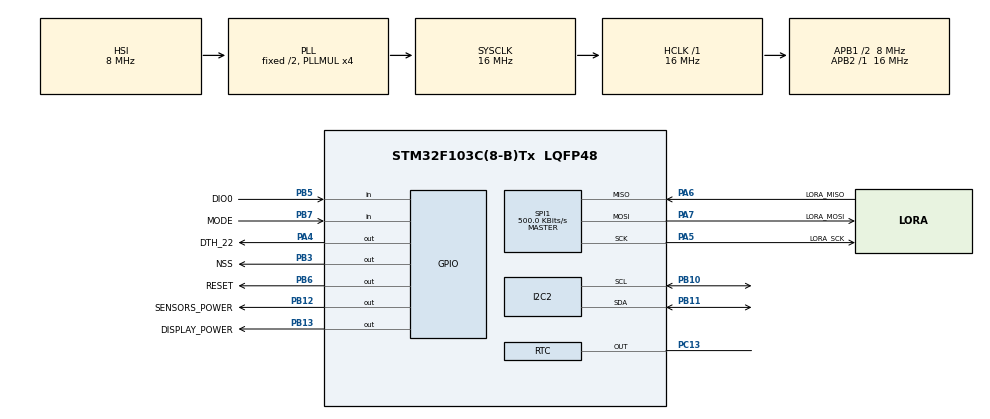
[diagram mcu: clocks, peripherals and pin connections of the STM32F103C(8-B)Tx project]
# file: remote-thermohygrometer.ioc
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Mcu.Family=STM32F1
Mcu.Name=STM32F103C(8-B)Tx
Mcu.Package=LQFP48
NVIC.PriorityGroup=NVIC_PRIORITYGROUP_4
PA0-WKUP.GPIO_Label=SYSTEM_WAKEUP
PA0-WKUP.Mode=SYS_WakeUp0
PA0-WKUP.Signal=SYS_WKUP
PA13.Mode=Serial_Wire
PA13.Signal=SYS_JTMS-SWDIO
PA14.Mode=Serial_Wire
PA14.Signal=SYS_JTCK-SWCLK
PA4.GPIO_Label=DTH_22
PA4.Signal=GPIO_Output
PA5.GPIO_Label=LORA_SCK
PA5.Mode=Full_Duplex_Master
PA5.Signal=SPI1_SCK
PA6.GPIO_Label=LORA_MISO
PA6.Mode=Full_Duplex_Master
PA6.Signal=SPI1_MISO
PA7.GPIO_Label=LORA_MOSI
PA7.Mode=Full_Duplex_Master
PA7.Signal=SPI1_MOSI
PB10.Mode=I2C
PB10.Signal=I2C2_SCL
PB11.Mode=I2C
PB11.Signal=I2C2_SDA
PB12.GPIO_Label=SENSORS_POWER
PB12.Signal=GPIO_Output
PB13.GPIO_Label=DISPLAY_POWER
PB13.Signal=GPIO_Output
PB3.GPIO_Label=NSS
PB3.PinState=GPIO_PIN_SET
PB3.Signal=GPIO_Output
PB5.GPIO_Label=DIO0
PB5.Signal=GPIO_Input
PB6.GPIO_Label=RESET
PB6.PinState=GPIO_PIN_SET
PB6.Signal=GPIO_Output
PB7.GPIO_Label=MODE
PB7.GPIO_PuPd=GPIO_PULLDOWN
PB7.Signal=GPIO_Input
PC13-TAMPER-RTC.Mode=RTC OUT
PC13-TAMPER-RTC.Signal=RTC_OUT
PD0-OSC_IN.Mode=HSE-External-Clock-Source
PD0-OSC_IN.Signal=RCC_OSC_IN
PD1-OSC_OUT.Mode=HSE-External-Clock-Source
PD1-OSC_OUT.Signal=RCC_OSC_OUT
ProjectManager.HeapSize=0x200
ProjectManager.StackSize=0x400
ProjectManager.TargetToolchain=STM32CubeIDE
RCC.AHBFreq_Value=16000000
RCC.APB1CLKDivider=RCC_HCLK_DIV2
RCC.APB1Freq_Value=8000000
RCC.APB1TimFreq_Value=16000000
RCC.APB2Freq_Value=16000000
RCC.APB2TimFreq_Value=16000000
RCC.HCLKFreq_Value=16000000
RCC.PLLMUL=RCC_PLL_MUL4
RCC.SYSCLKFreq_VALUE=16000000
RCC.SYSCLKSource=RCC_SYSCLKSOURCE_PLLCLK
RCC.USBFreq_Value=16000000
RTC.Minutes_A-RTC\ OUT=1
RTC.Seconds_A-RTC\ OUT=0
SPI1.BaudRatePrescaler=SPI_BAUDRATEPRESCALER_32
SPI1.CalculateBaudRate=500.0 KBits/s
SPI1.Direction=SPI_DIRECTION_2LINES
SPI1.Mode=SPI_MODE_MASTER
SPI1.VirtualType=VM_MASTER
TIM1.Prescaler=16-1
VP_RTC_VS_RTC_Activate.Mode=RTC_Enabled
VP_RTC_VS_RTC_Calendar.Mode=RTC_Calendar
VP_TIM1_VS_ClockSourceINT.Mode=Internal
board=custom

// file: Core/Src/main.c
/* USER CODE BEGIN Header */
/**
  ******************************************************************************
  * @file           : main.c
  * @brief          : Main program body
  ******************************************************************************
  * @attention
  *
  * Copyright (c) 2024 STMicroelectronics.
  * All rights reserved.
  *
  * This software is licensed under terms that can be found in the LICENSE file
  * in the root directory of this software component.
  * If no LICENSE file comes with this software, it is provided AS-IS.
  *
  ******************************************************************************
  */
/* USER CODE END Header */
#include "main.h"

/* USER CODE BEGIN Includes */
#include "App/app.h"
/* USER CODE END Includes */

I2C_HandleTypeDef hi2c2;

RTC_HandleTypeDef hrtc;

SPI_HandleTypeDef hspi1;

TIM_HandleTypeDef htim1;

void SystemClock_Config(void);
static void MX_GPIO_Init(void);
static void MX_SPI1_Init(void);
static void MX_I2C2_Init(void);
static void MX_TIM1_Init(void);
static void MX_RTC_Init(void);

int main(void)
{

  /* MCU Configuration--------------------------------------------------------*/

  /* Reset of all peripherals, Initializes the Flash interface and the Systick. */
  HAL_Init();

  /* Configure the system clock */
  SystemClock_Config();

  /* Initialize all configured peripherals */
  MX_GPIO_Init();
  MX_SPI1_Init();
  MX_I2C2_Init();
  MX_TIM1_Init();
  MX_RTC_Init();
  /* USER CODE BEGIN 2 */

  __HAL_PWR_CLEAR_FLAG(PWR_FLAG_WU);

  HAL_TIM_Base_Start(&htim1);
  appMain(&hi2c2, &hspi1);

  HAL_PWR_EnableWakeUpPin(PWR_WAKEUP_PIN1);
  HAL_PWR_EnterSTANDBYMode();
  //wake up with RTC alert
  /* USER CODE END 2 */

  /* Infinite loop */
  while (1)
  {

  }
}

void SystemClock_Config(void)
{
  RCC_OscInitTypeDef RCC_OscInitStruct = {0};
  RCC_ClkInitTypeDef RCC_ClkInitStruct = {0};
  RCC_PeriphCLKInitTypeDef PeriphClkInit = {0};

  /** Initializes the RCC Oscillators according to the specified parameters
  * in the RCC_OscInitTypeDef structure.
  */
  RCC_OscInitStruct.OscillatorType = RCC_OSCILLATORTYPE_HSI|RCC_OSCILLATORTYPE_LSI;
  RCC_OscInitStruct.HSIState = RCC_HSI_ON;
  RCC_OscInitStruct.HSICalibrationValue = RCC_HSICALIBRATION_DEFAULT;
  RCC_OscInitStruct.LSIState = RCC_LSI_ON;
  RCC_OscInitStruct.PLL.PLLState = RCC_PLL_ON;
  RCC_OscInitStruct.PLL.PLLSource = RCC_PLLSOURCE_HSI_DIV2;
  RCC_OscInitStruct.PLL.PLLMUL = RCC_PLL_MUL4;
  if (HAL_RCC_OscConfig(&RCC_OscInitStruct) != HAL_OK)
  {
    Error_Handler();
  }

  /** Initializes the CPU, AHB and APB buses clocks
  */
  RCC_ClkInitStruct.ClockType = RCC_CLOCKTYPE_HCLK|RCC_CLOCKTYPE_SYSCLK
                              |RCC_CLOCKTYPE_PCLK1|RCC_CLOCKTYPE_PCLK2;
  RCC_ClkInitStruct.SYSCLKSource = RCC_SYSCLKSOURCE_PLLCLK;
  RCC_ClkInitStruct.AHBCLKDivider = RCC_SYSCLK_DIV1;
  RCC_ClkInitStruct.APB1CLKDivider = RCC_HCLK_DIV2;
  RCC_ClkInitStruct.APB2CLKDivider = RCC_HCLK_DIV1;

  if (HAL_RCC_ClockConfig(&RCC_ClkInitStruct, FLASH_LATENCY_0) != HAL_OK)
  {
    Error_Handler();
  }
  PeriphClkInit.PeriphClockSelection = RCC_PERIPHCLK_RTC;
  PeriphClkInit.RTCClockSelection = RCC_RTCCLKSOURCE_LSI;
  if (HAL_RCCEx_PeriphCLKConfig(&PeriphClkInit) != HAL_OK)
  {
    Error_Handler();
  }
}

static void MX_I2C2_Init(void)
{

  hi2c2.Instance = I2C2;
  hi2c2.Init.ClockSpeed = 100000;
  hi2c2.Init.DutyCycle = I2C_DUTYCYCLE_2;
  hi2c2.Init.OwnAddress1 = 0;
  hi2c2.Init.AddressingMode = I2C_ADDRESSINGMODE_7BIT;
  hi2c2.Init.DualAddressMode = I2C_DUALADDRESS_DISABLE;
  hi2c2.Init.OwnAddress2 = 0;
  hi2c2.Init.GeneralCallMode = I2C_GENERALCALL_DISABLE;
  hi2c2.Init.NoStretchMode = I2C_NOSTRETCH_DISABLE;
  if (HAL_I2C_Init(&hi2c2) != HAL_OK)
  {
    Error_Handler();
  }

}

static void MX_RTC_Init(void)
{

  RTC_TimeTypeDef sTime = {0};
  RTC_DateTypeDef DateToUpdate = {0};
  RTC_AlarmTypeDef sAlarm = {0};

  /** Initialize RTC Only
  */
  hrtc.Instance = RTC;
  hrtc.Init.AsynchPrediv = RTC_AUTO_1_SECOND;
  hrtc.Init.OutPut = RTC_OUTPUTSOURCE_ALARM;
  if (HAL_RTC_Init(&hrtc) != HAL_OK)
  {
    Error_Handler();
  }

  /** Initialize RTC and set the Time and Date
  */
  sTime.Hours = 0x0;
  sTime.Minutes = 0x0;
  sTime.Seconds = 0x0;

  if (HAL_RTC_SetTime(&hrtc, &sTime, RTC_FORMAT_BCD) != HAL_OK)
  {
    Error_Handler();
  }
  DateToUpdate.WeekDay = RTC_WEEKDAY_MONDAY;
  DateToUpdate.Month = RTC_MONTH_JANUARY;
  DateToUpdate.Date = 0x1;
  DateToUpdate.Year = 0x0;

  if (HAL_RTC_SetDate(&hrtc, &DateToUpdate, RTC_FORMAT_BCD) != HAL_OK)
  {
    Error_Handler();
  }

  /** Enable the Alarm A
  */
  sAlarm.AlarmTime.Hours = 0x0;
  sAlarm.AlarmTime.Minutes = 0x1;
  sAlarm.AlarmTime.Seconds = 0x0;
  sAlarm.Alarm = RTC_ALARM_A;
  if (HAL_RTC_SetAlarm(&hrtc, &sAlarm, RTC_FORMAT_BCD) != HAL_OK)
  {
    Error_Handler();
  }

}

static void MX_SPI1_Init(void)
{

  /* SPI1 parameter configuration*/
  hspi1.Instance = SPI1;
  hspi1.Init.Mode = SPI_MODE_MASTER;
  hspi1.Init.Direction = SPI_DIRECTION_2LINES;
  hspi1.Init.DataSize = SPI_DATASIZE_8BIT;
  hspi1.Init.CLKPolarity = SPI_POLARITY_LOW;
  hspi1.Init.CLKPhase = SPI_PHASE_1EDGE;
  hspi1.Init.NSS = SPI_NSS_SOFT;
  hspi1.Init.BaudRatePrescaler = SPI_BAUDRATEPRESCALER_32;
  hspi1.Init.FirstBit = SPI_FIRSTBIT_MSB;
  hspi1.Init.TIMode = SPI_TIMODE_DISABLE;
  hspi1.Init.CRCCalculation = SPI_CRCCALCULATION_DISABLE;
  hspi1.Init.CRCPolynomial = 10;
  if (HAL_SPI_Init(&hspi1) != HAL_OK)
  {
    Error_Handler();
  }

}

static void MX_TIM1_Init(void)
{

  TIM_ClockConfigTypeDef sClockSourceConfig = {0};
  TIM_MasterConfigTypeDef sMasterConfig = {0};

  htim1.Instance = TIM1;
  htim1.Init.Prescaler = 16-1;
  htim1.Init.CounterMode = TIM_COUNTERMODE_UP;
  htim1.Init.Period = 65535;
  htim1.Init.ClockDivision = TIM_CLOCKDIVISION_DIV1;
  htim1.Init.RepetitionCounter = 0;
  htim1.Init.AutoReloadPreload = TIM_AUTORELOAD_PRELOAD_DISABLE;
  if (HAL_TIM_Base_Init(&htim1) != HAL_OK)
  {
    Error_Handler();
  }
  sClockSourceConfig.ClockSource = TIM_CLOCKSOURCE_INTERNAL;
  if (HAL_TIM_ConfigClockSource(&htim1, &sClockSourceConfig) != HAL_OK)
  {
    Error_Handler();
  }
  sMasterConfig.MasterOutputTrigger = TIM_TRGO_RESET;
  sMasterConfig.MasterSlaveMode = TIM_MASTERSLAVEMODE_DISABLE;
  if (HAL_TIMEx_MasterConfigSynchronization(&htim1, &sMasterConfig) != HAL_OK)
  {
    Error_Handler();
  }

}

static void MX_GPIO_Init(void)
{
  GPIO_InitTypeDef GPIO_InitStruct = {0};

  /* GPIO Ports Clock Enable */
  __HAL_RCC_GPIOC_CLK_ENABLE();
  __HAL_RCC_GPIOD_CLK_ENABLE();
  __HAL_RCC_GPIOA_CLK_ENABLE();
  __HAL_RCC_GPIOB_CLK_ENABLE();

  /*Configure GPIO pin Output Level */
  HAL_GPIO_WritePin(DTH_22_GPIO_Port, DTH_22_Pin, GPIO_PIN_RESET);

  /*Configure GPIO pin Output Level */
  HAL_GPIO_WritePin(GPIOB, SENSORS_POWER_Pin|DISPLAY_POWER_Pin, GPIO_PIN_RESET);

  /*Configure GPIO pin Output Level */
  HAL_GPIO_WritePin(GPIOB, NSS_Pin|RESET_Pin, GPIO_PIN_SET);

  /*Configure GPIO pins : PC14 PC15 */
  GPIO_InitStruct.Pin = GPIO_PIN_14|GPIO_PIN_15;
  GPIO_InitStruct.Mode = GPIO_MODE_ANALOG;
  HAL_GPIO_Init(GPIOC, &GPIO_InitStruct);

  /*Configure GPIO pins : PA1 PA2 PA3 PA8
                           PA9 PA10 PA11 PA12
                           PA15 */
  GPIO_InitStruct.Pin = GPIO_PIN_1|GPIO_PIN_2|GPIO_PIN_3|GPIO_PIN_8
                          |GPIO_PIN_9|GPIO_PIN_10|GPIO_PIN_11|GPIO_PIN_12
                          |GPIO_PIN_15;
  GPIO_InitStruct.Mode = GPIO_MODE_ANALOG;
  HAL_GPIO_Init(GPIOA, &GPIO_InitStruct);

  /*Configure GPIO pin : DTH_22_Pin */
  GPIO_InitStruct.Pin = DTH_22_Pin;
  GPIO_InitStruct.Mode = GPIO_MODE_OUTPUT_PP;
  GPIO_InitStruct.Pull = GPIO_NOPULL;
  GPIO_InitStruct.Speed = GPIO_SPEED_FREQ_LOW;
  HAL_GPIO_Init(DTH_22_GPIO_Port, &GPIO_InitStruct);

  /*Configure GPIO pins : PB0 PB1 PB2 PB14
                           PB15 PB4 PB8 PB9 */
  GPIO_InitStruct.Pin = GPIO_PIN_0|GPIO_PIN_1|GPIO_PIN_2|GPIO_PIN_14
                          |GPIO_PIN_15|GPIO_PIN_4|GPIO_PIN_8|GPIO_PIN_9;
  GPIO_InitStruct.Mode = GPIO_MODE_ANALOG;
  HAL_GPIO_Init(GPIOB, &GPIO_InitStruct);

  /*Configure GPIO pins : SENSORS_POWER_Pin DISPLAY_POWER_Pin NSS_Pin RESET_Pin */
  GPIO_InitStruct.Pin = SENSORS_POWER_Pin|DISPLAY_POWER_Pin|NSS_Pin|RESET_Pin;
  GPIO_InitStruct.Mode = GPIO_MODE_OUTPUT_PP;
  GPIO_InitStruct.Pull = GPIO_NOPULL;
  GPIO_InitStruct.Speed = GPIO_SPEED_FREQ_LOW;
  HAL_GPIO_Init(GPIOB, &GPIO_InitStruct);

  /*Configure GPIO pin : DIO0_Pin */
  GPIO_InitStruct.Pin = DIO0_Pin;
  GPIO_InitStruct.Mode = GPIO_MODE_INPUT;
  GPIO_InitStruct.Pull = GPIO_NOPULL;
  HAL_GPIO_Init(DIO0_GPIO_Port, &GPIO_InitStruct);

  /*Configure GPIO pin : MODE_Pin */
  GPIO_InitStruct.Pin = MODE_Pin;
  GPIO_InitStruct.Mode = GPIO_MODE_INPUT;
  GPIO_InitStruct.Pull = GPIO_PULLDOWN;
  HAL_GPIO_Init(MODE_GPIO_Port, &GPIO_InitStruct);

}

/* USER CODE BEGIN 4 */
void microDelay(uint32_t microSeconds)
{
    __HAL_TIM_SET_COUNTER(&htim1, 0);
    while (__HAL_TIM_GET_COUNTER(&htim1) < microSeconds);
}
/* USER CODE END 4 */

void Error_Handler(void)
{
  /* USER CODE BEGIN Error_Handler_Debug */
  /* User can add his own implementation to report the HAL error return state */
    NVIC_SystemReset();
  /* USER CODE END Error_Handler_Debug */
}
